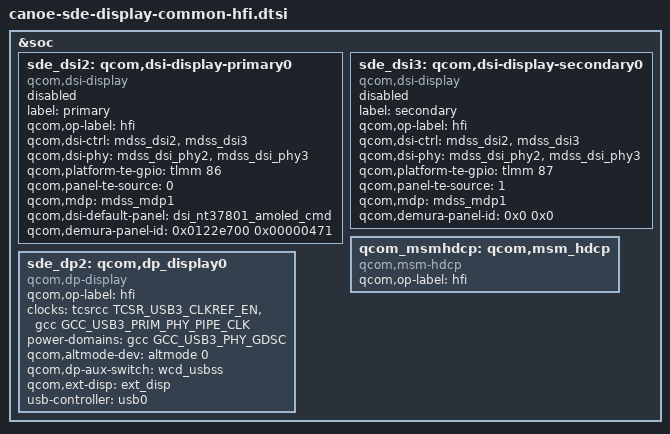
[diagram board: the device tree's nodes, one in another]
// SPDX-License-Identifier: BSD-3-Clause
/*
 * Copyright (c) Qualcomm Technologies, Inc. and/or its subsidiaries.
 */
#include <dt-bindings/clock/qcom,gcc-canoe.h>
#include <dt-bindings/clock/qcom,tcsrcc-canoe.h>

&soc {

	sde_dsi2: qcom,dsi-display-primary0 {
		compatible = "qcom,dsi-display";
		label = "primary";
		qcom,op-label = "hfi";
		status = "disabled";

		qcom,dsi-ctrl = <&mdss_dsi2 &mdss_dsi3>;
		qcom,dsi-phy = <&mdss_dsi_phy2 &mdss_dsi_phy3>;

		qcom,platform-te-gpio = <&tlmm 86 0>;
		qcom,panel-te-source = <0>;

		qcom,mdp = <&mdss_mdp1>;
		qcom,dsi-default-panel = <&dsi_nt37801_amoled_cmd>;
		qcom,demura-panel-id = <0x0122e700 0x00000471>;
	};

	sde_dsi3: qcom,dsi-display-secondary0 {
		compatible = "qcom,dsi-display";
		label = "secondary";
		qcom,op-label = "hfi";
		status = "disabled";

		qcom,dsi-ctrl = <&mdss_dsi2 &mdss_dsi3>;
		qcom,dsi-phy = <&mdss_dsi_phy2 &mdss_dsi_phy3>;

		qcom,platform-te-gpio = <&tlmm 87 0>;
		qcom,panel-te-source = <1>;

		qcom,mdp = <&mdss_mdp1>;
		qcom,demura-panel-id = <0x0 0x0>;
	};

	qcom_msmhdcp: qcom,msm_hdcp {
		compatible = "qcom,msm-hdcp";
		qcom,op-label = "hfi";
		status = "ok";
	};

	sde_dp2: qcom,dp_display0 {
		compatible = "qcom,dp-display";
		qcom,op-label = "hfi";
		status = "ok";

		#clock-cells = <1>;
		clocks = <&tcsrcc TCSR_USB3_CLKREF_EN>,
			<&gcc GCC_USB3_PRIM_PHY_PIPE_CLK>;
		clock-names = "usb3_tcsr_clk", "usb3_pipe_clk";
		power-domains = <&gcc GCC_USB3_PHY_GDSC>;
		qcom,altmode-dev = <&altmode 0>;
		qcom,dp-aux-switch = <&wcd_usbss>;
		qcom,ext-disp = <&ext_disp>;
		usb-controller = <&usb0>;
	};
};
